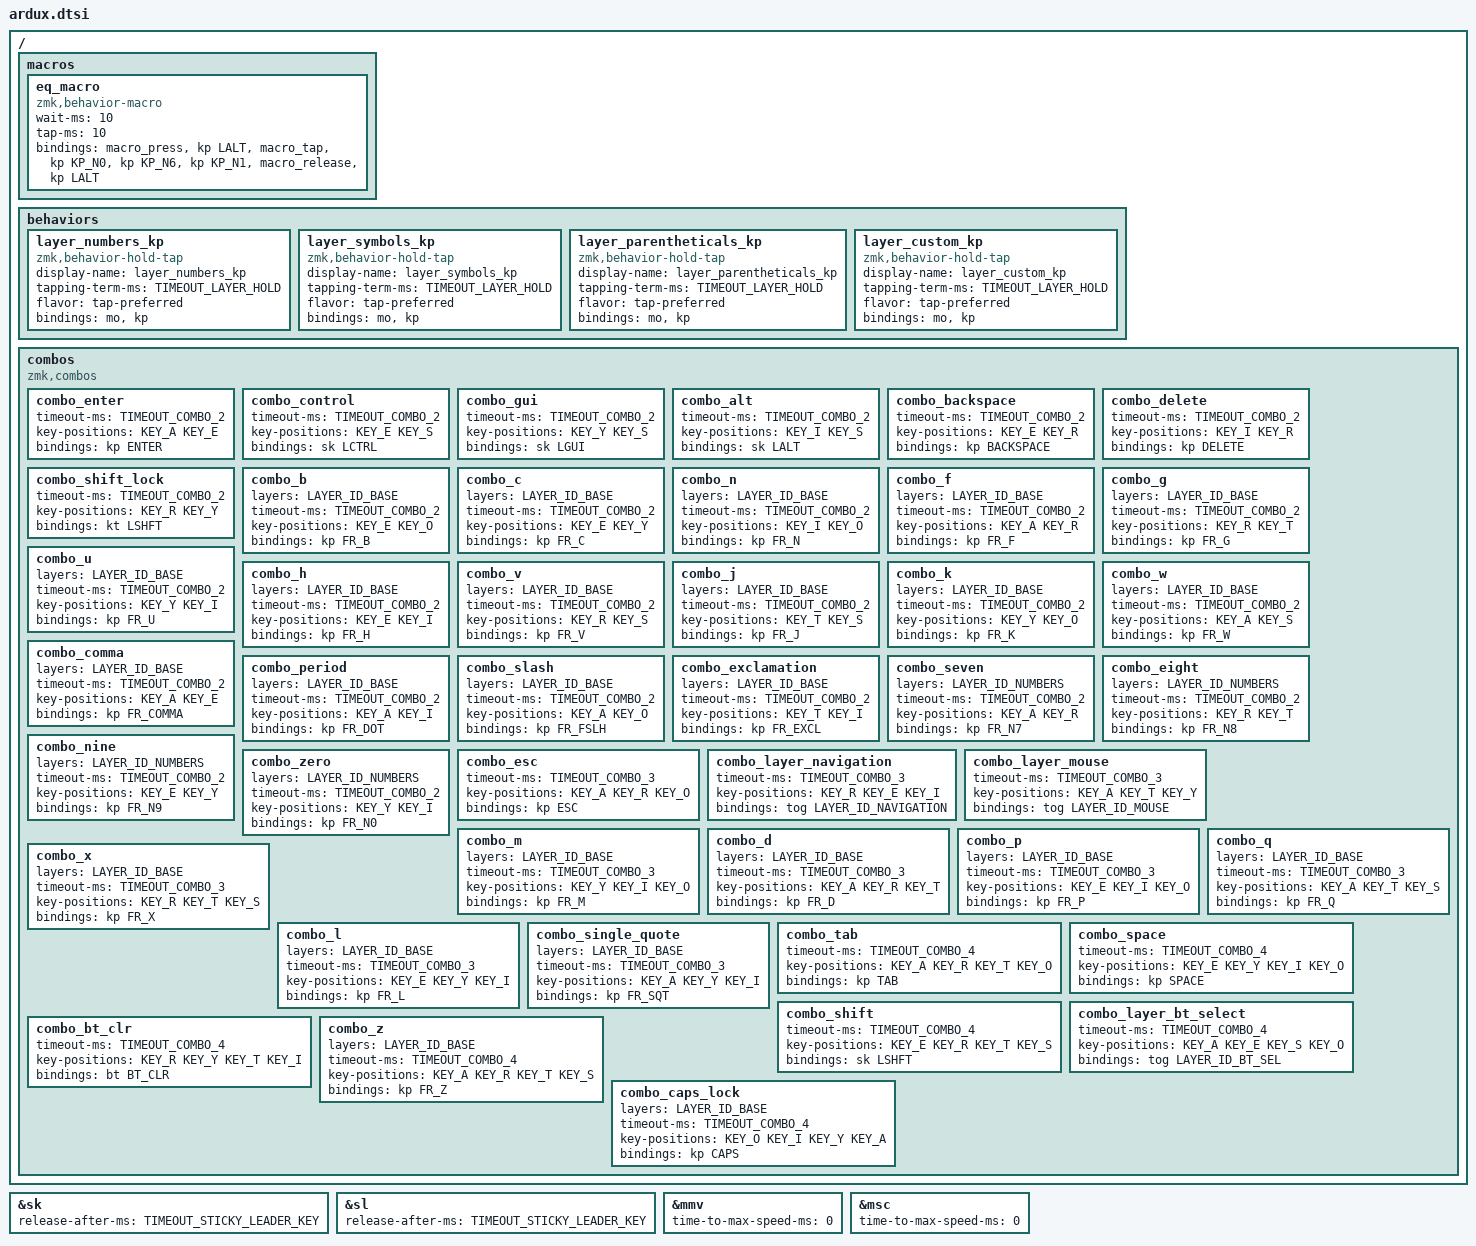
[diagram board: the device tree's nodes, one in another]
/*
 * Copyright (c) 2021 Mike "KemoNine" Crosson
 * SPDX-License-Identifier: MIT
 *
 * Belgian French ARDUX implementation for the Paintbrush Left
 * Uses keys_fr_belgian.h for all locale-specific keycodes
 */

#include <behaviors.dtsi>
#include <dt-bindings/zmk/keys.h>
#include <dt-bindings/zmk/outputs.h>
#include <dt-bindings/zmk/pointing.h>
#include "keys_fr_belgian.h"

// ---------------------------------------------------------------
// NONE macros (for padding)
// ---------------------------------------------------------------
#define NONE0(X)
#define NONE1(X) X
#define NONE2(X) NONE1(X) X
#define NONE3(X) NONE2(X) X
#define NONE4(X) NONE3(X) X
#define NONE5(X) NONE4(X) X
#define NONE6(X) NONE5(X) X
#define NONE7(X) NONE6(X) X
#define NONE8(X) NONE7(X) X
#define NONE9(X) NONE8(X) X
#define NONE10(X) NONE9(X) X
#define NONE(HUNDREDS,TENS,ONES) \
  NONE##HUNDREDS(NONE10(NONE10(&none))) \
  NONE##TENS(NONE10(&none)) \
  NONE##ONES(&none)

// ---------------------------------------------------------------
// Timeouts
// ---------------------------------------------------------------
#if !defined TIMEOUT_COMBO_2
#define TIMEOUT_COMBO_2 175
#endif
#if !defined TIMEOUT_COMBO_3
#define TIMEOUT_COMBO_3 175
#endif
#if !defined TIMEOUT_COMBO_4
#define TIMEOUT_COMBO_4 175
#endif
#if !defined TIMEOUT_LAYER_HOLD
#define TIMEOUT_LAYER_HOLD 200
#endif
#if !defined TIMEOUT_STICKY_LEADER_KEY
#define TIMEOUT_STICKY_LEADER_KEY 5000
#endif

&sk { release-after-ms = <TIMEOUT_STICKY_LEADER_KEY>; };
&sl { release-after-ms = <TIMEOUT_STICKY_LEADER_KEY>; };
&mmv { time-to-max-speed-ms = <0>; };
&msc { time-to-max-speed-ms = <0>; };

// ---------------------------------------------------------------
// Layer IDs
// ---------------------------------------------------------------
#define LAYER_ID_BASE           0
#define LAYER_ID_NUMBERS        1
#define LAYER_ID_SYMBOLS        2
#define LAYER_ID_PARENTHETICALS 3
#define LAYER_ID_NAVIGATION     4
#define LAYER_ID_BT_SEL         5
#define LAYER_ID_MOUSE          6
#define LAYER_ID_CUSTOM         7

// ---------------------------------------------------------------
// Macros
// = sign: no direct key on Belgian French, use Windows Alt+numpad
// ---------------------------------------------------------------
/ {
    macros {
        eq_macro: eq_macro {
            compatible = "zmk,behavior-macro";
            #binding-cells = <0>;
            wait-ms = <10>;
            tap-ms = <10>;
            bindings
                = <&macro_press &kp LALT>
                , <&macro_tap &kp KP_N0 &kp KP_N6 &kp KP_N1>
                , <&macro_release &kp LALT>
                ;
        };
    };
};

// ---------------------------------------------------------------
// Behaviors
// ---------------------------------------------------------------
/ {
    behaviors {
        layer_numbers_kp: layer_numbers_kp {
            compatible = "zmk,behavior-hold-tap";
            display-name = "layer_numbers_kp";
            #binding-cells = <2>;
            tapping-term-ms = <TIMEOUT_LAYER_HOLD>;
            flavor = "tap-preferred";
            bindings = <&mo>, <&kp>;
        };
        layer_symbols_kp: layer_symbols_kp {
            compatible = "zmk,behavior-hold-tap";
            display-name = "layer_symbols_kp";
            #binding-cells = <2>;
            tapping-term-ms = <TIMEOUT_LAYER_HOLD>;
            flavor = "tap-preferred";
            bindings = <&mo>, <&kp>;
        };
        layer_parentheticals_kp: layer_parentheticals_kp {
            compatible = "zmk,behavior-hold-tap";
            display-name = "layer_parentheticals_kp";
            #binding-cells = <2>;
            tapping-term-ms = <TIMEOUT_LAYER_HOLD>;
            flavor = "tap-preferred";
            bindings = <&mo>, <&kp>;
        };
        layer_custom_kp: layer_custom_kp {
            compatible = "zmk,behavior-hold-tap";
            display-name = "layer_custom_kp";
            #binding-cells = <2>;
            tapping-term-ms = <TIMEOUT_LAYER_HOLD>;
            flavor = "tap-preferred";
            bindings = <&mo>, <&kp>;
        };
    };
};

// ---------------------------------------------------------------
// Combos
// All letter keycodes now use FR_ names from keys_fr_belgian.h
// ---------------------------------------------------------------
/ {
    combos {
        compatible = "zmk,combos";

        // --- Global utility combos ---
        combo_enter        { timeout-ms = <TIMEOUT_COMBO_2>; key-positions = <KEY_A KEY_E>; bindings = <&kp ENTER>; };
        combo_control      { timeout-ms = <TIMEOUT_COMBO_2>; key-positions = <KEY_E KEY_S>; bindings = <&sk LCTRL>; };
        combo_gui          { timeout-ms = <TIMEOUT_COMBO_2>; key-positions = <KEY_Y KEY_S>; bindings = <&sk LGUI>; };
        combo_alt          { timeout-ms = <TIMEOUT_COMBO_2>; key-positions = <KEY_I KEY_S>; bindings = <&sk LALT>; };
        combo_backspace    { timeout-ms = <TIMEOUT_COMBO_2>; key-positions = <KEY_E KEY_R>; bindings = <&kp BACKSPACE>; };
        combo_delete       { timeout-ms = <TIMEOUT_COMBO_2>; key-positions = <KEY_I KEY_R>; bindings = <&kp DELETE>; };
        combo_shift_lock   { timeout-ms = <TIMEOUT_COMBO_2>; key-positions = <KEY_R KEY_Y>; bindings = <&kt LSHFT>; };

        // --- 2-key letter combos (base layer) ---
        combo_b  { layers = <LAYER_ID_BASE>; timeout-ms = <TIMEOUT_COMBO_2>; key-positions = <KEY_E KEY_O>; bindings = <&kp FR_B>; };
        combo_c  { layers = <LAYER_ID_BASE>; timeout-ms = <TIMEOUT_COMBO_2>; key-positions = <KEY_E KEY_Y>; bindings = <&kp FR_C>; };
        combo_n  { layers = <LAYER_ID_BASE>; timeout-ms = <TIMEOUT_COMBO_2>; key-positions = <KEY_I KEY_O>; bindings = <&kp FR_N>; };
        combo_f  { layers = <LAYER_ID_BASE>; timeout-ms = <TIMEOUT_COMBO_2>; key-positions = <KEY_A KEY_R>; bindings = <&kp FR_F>; };
        combo_g  { layers = <LAYER_ID_BASE>; timeout-ms = <TIMEOUT_COMBO_2>; key-positions = <KEY_R KEY_T>; bindings = <&kp FR_G>; };
        combo_u  { layers = <LAYER_ID_BASE>; timeout-ms = <TIMEOUT_COMBO_2>; key-positions = <KEY_Y KEY_I>; bindings = <&kp FR_U>; };
        combo_h  { layers = <LAYER_ID_BASE>; timeout-ms = <TIMEOUT_COMBO_2>; key-positions = <KEY_E KEY_I>; bindings = <&kp FR_H>; };
        combo_v  { layers = <LAYER_ID_BASE>; timeout-ms = <TIMEOUT_COMBO_2>; key-positions = <KEY_R KEY_S>; bindings = <&kp FR_V>; };
        combo_j  { layers = <LAYER_ID_BASE>; timeout-ms = <TIMEOUT_COMBO_2>; key-positions = <KEY_T KEY_S>; bindings = <&kp FR_J>; };
        combo_k  { layers = <LAYER_ID_BASE>; timeout-ms = <TIMEOUT_COMBO_2>; key-positions = <KEY_Y KEY_O>; bindings = <&kp FR_K>; };
        combo_w  { layers = <LAYER_ID_BASE>; timeout-ms = <TIMEOUT_COMBO_2>; key-positions = <KEY_A KEY_S>; bindings = <&kp FR_W>; };

        // --- Punctuation combos (base layer) ---
        // FR_COMMA = M key unshifted = ,
        // FR_DOT   = LS(COMMA key) = .
        // FR_FSLH  = LS(PERIOD key) = /
        // FR_EXCL  = 8 key unshifted = !
        combo_comma        { layers = <LAYER_ID_BASE>; timeout-ms = <TIMEOUT_COMBO_2>; key-positions = <KEY_A KEY_E>; bindings = <&kp FR_COMMA>; };
        combo_period       { layers = <LAYER_ID_BASE>; timeout-ms = <TIMEOUT_COMBO_2>; key-positions = <KEY_A KEY_I>; bindings = <&kp FR_DOT>; };
        combo_slash        { layers = <LAYER_ID_BASE>; timeout-ms = <TIMEOUT_COMBO_2>; key-positions = <KEY_A KEY_O>; bindings = <&kp FR_FSLH>; };
        combo_exclamation  { layers = <LAYER_ID_BASE>; timeout-ms = <TIMEOUT_COMBO_2>; key-positions = <KEY_T KEY_I>; bindings = <&kp FR_EXCL>; };

        // --- Number layer combos (7, 8, 9, 0) ---
        combo_seven { layers = <LAYER_ID_NUMBERS>; timeout-ms = <TIMEOUT_COMBO_2>; key-positions = <KEY_A KEY_R>; bindings = <&kp FR_N7>; };
        combo_eight { layers = <LAYER_ID_NUMBERS>; timeout-ms = <TIMEOUT_COMBO_2>; key-positions = <KEY_R KEY_T>; bindings = <&kp FR_N8>; };
        combo_nine  { layers = <LAYER_ID_NUMBERS>; timeout-ms = <TIMEOUT_COMBO_2>; key-positions = <KEY_E KEY_Y>; bindings = <&kp FR_N9>; };
        combo_zero  { layers = <LAYER_ID_NUMBERS>; timeout-ms = <TIMEOUT_COMBO_2>; key-positions = <KEY_Y KEY_I>; bindings = <&kp FR_N0>; };

        // --- 3-key letter combos (base layer) ---
        combo_esc              { timeout-ms = <TIMEOUT_COMBO_3>; key-positions = <KEY_A KEY_R KEY_O>; bindings = <&kp ESC>; };
        combo_layer_navigation { timeout-ms = <TIMEOUT_COMBO_3>; key-positions = <KEY_R KEY_E KEY_I>; bindings = <&tog LAYER_ID_NAVIGATION>; };
        combo_layer_mouse      { timeout-ms = <TIMEOUT_COMBO_3>; key-positions = <KEY_A KEY_T KEY_Y>; bindings = <&tog LAYER_ID_MOUSE>; };

        combo_m  { layers = <LAYER_ID_BASE>; timeout-ms = <TIMEOUT_COMBO_3>; key-positions = <KEY_Y KEY_I KEY_O>; bindings = <&kp FR_M>; };
        combo_d  { layers = <LAYER_ID_BASE>; timeout-ms = <TIMEOUT_COMBO_3>; key-positions = <KEY_A KEY_R KEY_T>; bindings = <&kp FR_D>; };
        combo_p  { layers = <LAYER_ID_BASE>; timeout-ms = <TIMEOUT_COMBO_3>; key-positions = <KEY_E KEY_I KEY_O>; bindings = <&kp FR_P>; };
        combo_q  { layers = <LAYER_ID_BASE>; timeout-ms = <TIMEOUT_COMBO_3>; key-positions = <KEY_A KEY_T KEY_S>; bindings = <&kp FR_Q>; };
        combo_x  { layers = <LAYER_ID_BASE>; timeout-ms = <TIMEOUT_COMBO_3>; key-positions = <KEY_R KEY_T KEY_S>; bindings = <&kp FR_X>; };
        combo_l  { layers = <LAYER_ID_BASE>; timeout-ms = <TIMEOUT_COMBO_3>; key-positions = <KEY_E KEY_Y KEY_I>; bindings = <&kp FR_L>; };

        // FR_SQT = key 4 unshifted = '
        combo_single_quote { layers = <LAYER_ID_BASE>; timeout-ms = <TIMEOUT_COMBO_3>; key-positions = <KEY_A KEY_Y KEY_I>; bindings = <&kp FR_SQT>; };

        // --- 4-key combos ---
        combo_tab             { timeout-ms = <TIMEOUT_COMBO_4>; key-positions = <KEY_A KEY_R KEY_T KEY_O>; bindings = <&kp TAB>; };
        combo_space           { timeout-ms = <TIMEOUT_COMBO_4>; key-positions = <KEY_E KEY_Y KEY_I KEY_O>; bindings = <&kp SPACE>; };
        combo_shift           { timeout-ms = <TIMEOUT_COMBO_4>; key-positions = <KEY_E KEY_R KEY_T KEY_S>; bindings = <&sk LSHFT>; };
        combo_layer_bt_select { timeout-ms = <TIMEOUT_COMBO_4>; key-positions = <KEY_A KEY_E KEY_S KEY_O>; bindings = <&tog LAYER_ID_BT_SEL>; };
        combo_bt_clr          { timeout-ms = <TIMEOUT_COMBO_4>; key-positions = <KEY_R KEY_Y KEY_T KEY_I>; bindings = <&bt BT_CLR>; };

        combo_z         { layers = <LAYER_ID_BASE>; timeout-ms = <TIMEOUT_COMBO_4>; key-positions = <KEY_A KEY_R KEY_T KEY_S>; bindings = <&kp FR_Z>; };
        combo_caps_lock { layers = <LAYER_ID_BASE>; timeout-ms = <TIMEOUT_COMBO_4>; key-positions = <KEY_O KEY_I KEY_Y KEY_A>; bindings = <&kp CAPS>; };
    };
};
